# ESP32-S31 register map
Vendor: ESPRESSIF SYSTEMS (SHANGHAI) CO., LTD.; Series: ESP32 S-Series; File version: 1
CPU: RV32IMAFC r0p0, little endian, no MPU, FPU, 0 interrupt priority bits
Address unit: 32 bits
Registers are 32-bit, read-write, reset 0x0 unless marked. A register's access mark holds for its fields unless they carry their own. Offsets are from the block's base; [hi:lo] are bit positions; {n}, {i} and the like mark numbered series; <NAME> marks a mode.

## LP_GPIO — Low-power General Purpose Input/Output
Base 0x20713000
0x04 OUT — LP_GPIO output register
  [7:0] DATA_ORIG — Configures the output value of LP_GPIO0 ~ 7 output in simple LP_GPIO output mode.\\ 0: Low level\\ 1: High level\\ The value of bit0 ~ bit7 correspond to the output value of LP_GPIO0 ~ LP_GPIO7 respectively. Bitxx ~ bitxx is invalid.\\
0x08 OUT_W1TS wo — LP_GPIO output set register
  [7:0] OUT_W1TS — Configures whether or not to set the output register LP_GPIO_OUT_REG of LP_GPIO0 ~ LP_GPIO7.\\ 0: Not set\\ 1: The corresponding bit in LP_GPIO_OUT_REG will be set to 1\\ Bit0 ~ bit7 are corresponding to LP_GPIO0 ~ LP_GPIO7. Bitxx ~ bitxx is invalid. \\ Recommended operation: use this register to set LP_GPIO_OUT_REG. \\
0x0C OUT_W1TC wo — LP_GPIO output clear register
  [7:0] OUT_W1TC — Configures whether or not to clear the output register LP_GPIO_OUT_REG of LP_GPIO0 ~ LP_GPIO7 output.\\ 0: Not clear\\ 1: The corresponding bit in LP_GPIO_OUT_REG will be cleared.\\ Bit0 ~ bit7 are corresponding to LP_GPIO0 ~ LP_GPIO7. Bitxx ~ bitxx is invalid. \\ Recommended operation: use this register to clear LP_GPIO_OUT_REG. \\
0x10 ENABLE — LP_GPIO output enable register
  [7:0] DATA — Configures whether or not to enable the output of LP_GPIO0 ~ LP_GPIO7.\\ 0: Not enable\\ 1: Enable\\ Bit0 ~ bit7 are corresponding to LP_GPIO0 ~ LP_GPIO7. Bitxx ~ bitxx is invalid.\\
0x14 ENABLE_W1TS wo — LP_GPIO output enable set register
  [7:0] ENABLE_W1TS — Configures whether or not to set the output enable register LP_GPIO_ENABLE_REG of LP_GPIO0 ~ LP_GPIO7.\\ 0: Not set\\ 1: The corresponding bit in LP_GPIO_ENABLE_REG will be set to 1\\ Bit0 ~ bit7 are corresponding to LP_GPIO0 ~ LP_GPIO7. Bitxx ~ bitxx is invalid. \\ Recommended operation: use this register to set LP_GPIO_ENABLE_REG.\\
0x18 ENABLE_W1TC wo — LP_GPIO output enable clear register
  [7:0] ENABLE_W1TC — Configures whether or not to clear the output enable register LP_GPIO_ENABLE_REG of LP_GPIO0 ~ LP_GPIO7. \\ 0: Not clear\\ 1: The corresponding bit in LP_GPIO_ENABLE_REG will be cleared\\ Bit0 ~ bit7 are corresponding to LP_GPIO0 ~ LP_GPIO7. Bitxx ~ bitxx is invalid. \\ Recommended operation: use this register to clear LP_GPIO_ENABLE_REG.\\
0x1C IN ro — LP_GPIO input register
  [7:0] DATA_NEXT — Represents the input value of LP_GPIO0 ~ LP_GPIO7. Each bit represents a pin input value:\\ 0: Low level\\ 1: High level\\ Bit0 ~ bit7 are corresponding to LP_GPIO0 ~ LP_GPIO7. Bitxx ~ bitxx is invalid.\\
0x20 STATUS — LP_GPIO interrupt status register
  [7:0] INTERRUPT — The interrupt status of LP_GPIO0 ~ LP_GPIO7, can be configured by the software. - Bit0 ~ bit7 are corresponding to LP_GPIO0 ~ LP_GPIO7. Bitxx ~ bitxx is invalid. - Each bit represents the status of its corresponding LP_GPIO: - 0: Represents the LP_GPIO does not generate the interrupt configured by LP_GPIO_PIN0_INT_TYPE, or this bit is configured to 0 by the software. - 1: Represents the LP_GPIO generates the interrupt configured by LP_GPIO_PIN0_INT_TYPE, or this bit is configured to 1 by the software.
0x24 STATUS_W1TS wo — LP_GPIO interrupt status set register
  [7:0] STATUS_W1TS — Configures whether or not to set the interrupt status register LP_GPIO_STATUS_INTERRUPT of LP_GPIO0 ~ LP_GPIO7. - Bit0 ~ bit7 are corresponding to LP_GPIO0 ~ LP_GPIO7. Bitxx ~ bitxx is invalid. - If the value 1 is written to a bit here, the corresponding bit in LP_GPIO_STATUS_INTERRUPT will be set to 1. \item Recommended operation: use this register to set LP_GPIO_STATUS_INTERRUPT.
0x28 STATUS_W1TC wo — LP_GPIO interrupt status clear register
  [7:0] STATUS_W1TC — Configures whether or not to clear the interrupt status register LP_GPIO_STATUS_INTERRUPT of LP_GPIO0 ~ LP_GPIO7. - Bit0 ~ bit7 are corresponding to LP_GPIO0 ~ LP_GPIO7. Bitxx ~ bitxx is invalid. - If the value 1 is written to a bit here, the corresponding bit in LP_GPIO_STATUS_INTERRUPT will be cleared. \item Recommended operation: use this register to clear LP_GPIO_STATUS_INTERRUPT.
0x2C STATUS_NEXT ro — LP_GPIO interrupt source register
  [7:0] STATUS_INTERRUPT_NEXT — Represents the interrupt source signal of LP_GPIO0 ~ LP_GPIO7.\\ Bit0 ~ bit24 are corresponding to LP_GPIO0 ~ LP_GPIO7. Bitxx ~ bitxx is invalid. Each bit represents:\\ 0: The LP_GPIO does not generate the interrupt configured by LP_GPIO_PIN0_INT_TYPE.\\ 1: The LP_GPIO generates an interrupt configured by LP_GPIO_PIN0_INT_TYPE.\\ The interrupt could be rising edge interrupt, falling edge interrupt, level sensitive interrupt and any edge interrupt.\\
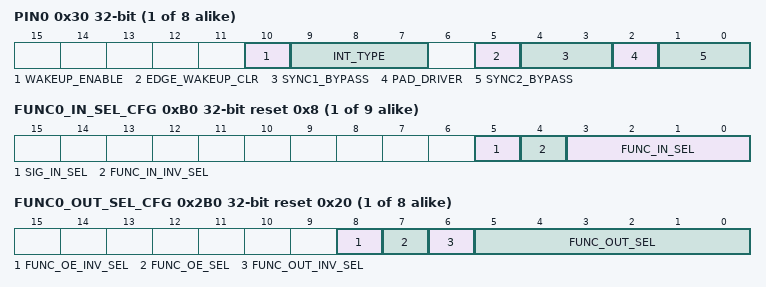
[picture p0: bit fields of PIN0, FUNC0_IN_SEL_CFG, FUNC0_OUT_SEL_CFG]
{0x30+4i} PIN{i} (i=0..7) access per field — LP_GPIO{i} configuration register
  [10] WAKEUP_ENABLE rw — Configures whether or not to enable LP_GPIO wake-up function.\\ 0: Disable\\ 1: Enable\\ This function only wakes up the CPU from Light-sleep. \\
  [9:7] INT_TYPE rw — Configures LP_GPIO interrupt type.\\ 0: LP_GPIO interrupt disabled\\ 1: Rising edge trigger\\ 2: Falling edge trigger\\ 3: Any edge trigger\\ 4: Low level trigger\\ 5: High level trigger\\
  [5] EDGE_WAKEUP_CLR wo — LP_GPIO wakeup clear register.
  [4:3] SYNC1_BYPASS rw — Configures whether or not to synchronize LP_GPIO input data on either edge of LP IO MUX operating clock for the first-level synchronization.\\ 0: Not synchronize\\ 1: Synchronize on falling edge\\ 2: Synchronize on rising edge\\ 3: Synchronize on rising edge\\
  [2] PAD_DRIVER rw — Configures to select pin drive mode. \\ 0: Normal output\\ 1: Open drain output \\
  [1:0] SYNC2_BYPASS rw — Configures whether or not to synchronize LP_GPIO input data on either edge of LP IO MUX operating clock for the second-level synchronization.\\ 0: Not synchronize\\ 1: Synchronize on falling edge\\ 2: Synchronize on rising edge\\ 3: Synchronize on rising edge\\
{0xB0+4i} FUNC{i}_IN_SEL_CFG (i=0..8) reset 0x8 — Configuration register for input signal {i}
  [5] SIG_IN_SEL — Configures whether or not to route signals via LP_GPIO matrix.\\ 0: Bypass LP_GPIO matrix, i.e., connect signals directly to peripheral configured in IO MUX.\\ 1: Route signals via LP_GPIO matrix.\\
  [4] FUNC_IN_INV_SEL — Configures whether or not to invert the input value.\\ 0: Not invert\\ 1: Invert\\
  [3:0] FUNC_IN_SEL — Configures to select a pin from the 8 LP_GPIO pins to connect the input signal %s.\\ 0: Select LP_GPIO0\\ 1: Select LP_GPIO1\\ ......\\ 6: Select LP_GPIO6\\ 7: Select LP_GPIO7\\ Or\\ 0x8: A constantly high input\\ 0xc: A constantly low input\\
{0x2B0+4i} FUNC{i}_OUT_SEL_CFG (i=0..7) reset 0x20 — Configuration register for LP_GPIO{i} output
  [8] FUNC_OE_INV_SEL — Configures whether or not to invert the output enable signal.\\ 0: Not invert\\ 1: Invert\\
  [7] FUNC_OE_SEL — Configures to select the source of output enable signal.\\ 0: Use output enable signal from peripheral.\\ 1: Force the output enable signal to be sourced from bit %s of LP_GPIO_ENABLE_REG. \\
  [6] FUNC_OUT_INV_SEL — Configures whether or not to invert the output value.\\ 0: Not invert\\ 1: Invert\\
  [5:0] FUNC_OUT_SEL — Configures to select a signal 0 (0 <= 0 < 32) from 32 peripheral signals to be output from LP_GPIO%s.\\ 0: Select signal 0\\ 1: Select signal 1\\ ......\\ 30: Select signal 30\\ 31: Select signal 31\\ Or\\ 32: Bit %s of LP_GPIO_OUT_REG and LP_GPIO_ENABLE_REG are selected as the output value and output enable. For the detailed signal list, see Table <a href=tab:iomuxgpio-periph-signals-via-gpio-matrix">link</a>. "
0x3F8 CLOCK_GATE reset 0x1 — LP_GPIO clock gate register
  [0] CLK_EN — Configures whether or not to enable clock gate.\\ 0: Not enable\\ 1: Enable, the clock is free running. \\
0x3FC DATE reset 0x2507040 — LP_GPIO version register
  [27:0] DATE — Version control register. \\
